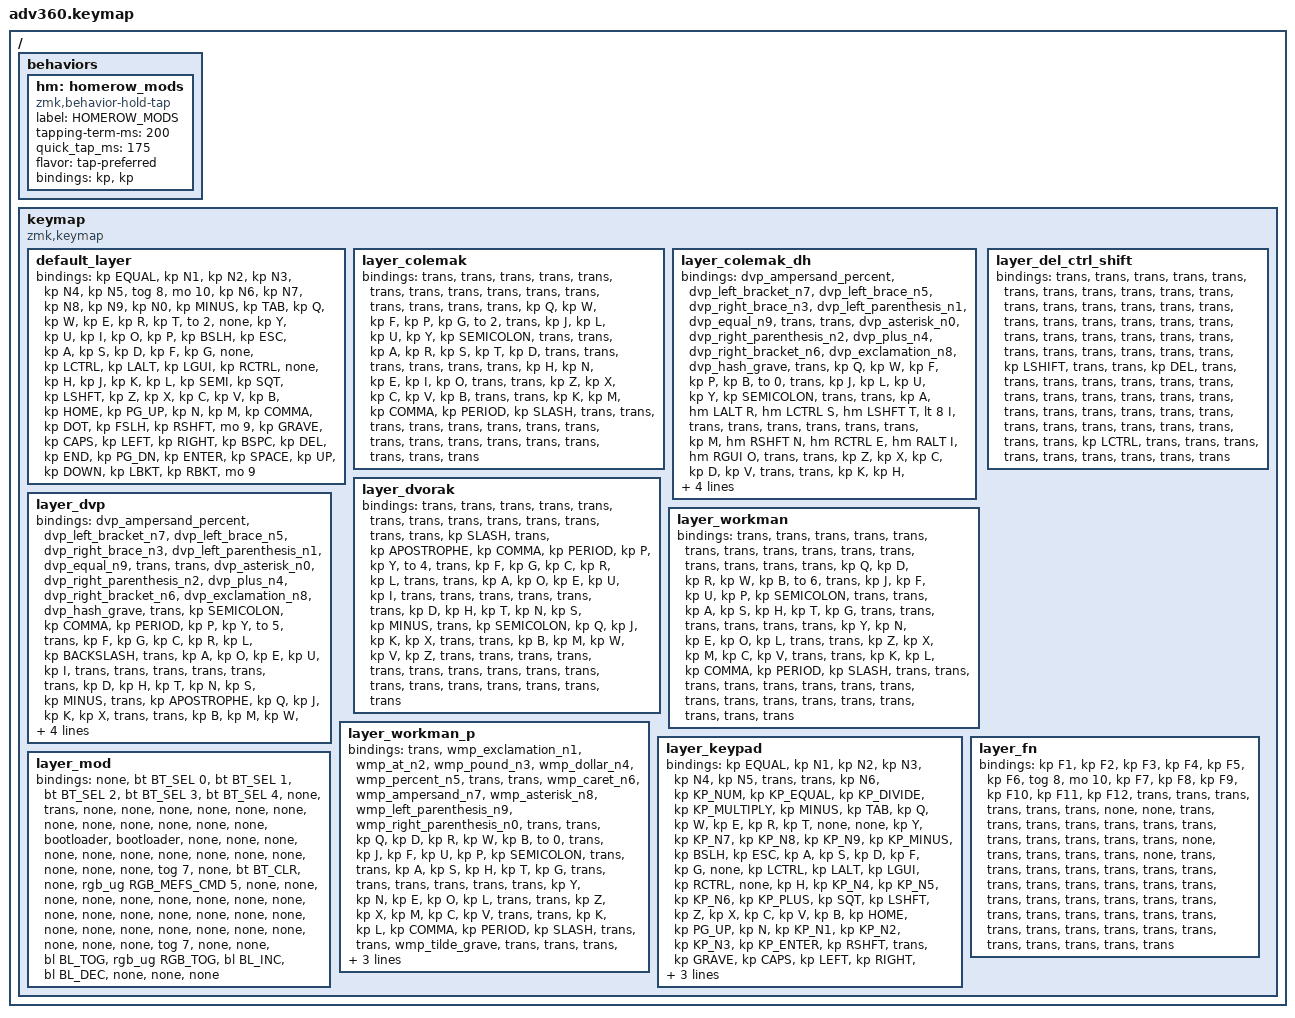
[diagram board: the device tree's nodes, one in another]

/*
 * Copyright (c) 2020 The ZMK Contributors
 *
 * SPDX-License-Identifier: MIT
 */


/* THIS FILE WAS GENERATED!
 *
 * This file was generated automatically. You may or may not want to
 * edit it directly.
 */

#include <behaviors.dtsi>
#include <dt-bindings/zmk/keys.h>
#include <dt-bindings/zmk/bt.h>
#include <dt-bindings/zmk/rgb.h>
#include <dt-bindings/zmk/backlight.h>

/ {
  behaviors {
    #include "macros.dtsi"
    #include "version.dtsi"

    hm: homerow_mods {
        compatible = "zmk,behavior-hold-tap";
        label = "HOMEROW_MODS";
        #binding-cells = <2>;
        tapping-term-ms = <200>;
        quick_tap_ms = <175>;
        flavor = "tap-preferred";
        bindings = <&kp>, <&kp>;
    };
  };

    keymap {
        compatible = "zmk,keymap";


        default_layer {
            bindings = <
 &kp EQUAL     &kp N1    &kp N2    &kp N3     &kp N4  &kp N5              &tog 8                                                                &mo 10  &kp N6  &kp N7     &kp N8    &kp N9    &kp N0  &kp MINUS
   &kp TAB      &kp Q     &kp W     &kp E      &kp R   &kp T               &to 2                                                                 &none   &kp Y   &kp U      &kp I     &kp O     &kp P   &kp BSLH
   &kp ESC      &kp A     &kp S     &kp D      &kp F   &kp G               &none  &kp LCTRL  &kp LALT                   &kp LGUI  &kp RCTRL      &none   &kp H   &kp J      &kp K     &kp L  &kp SEMI    &kp SQT
 &kp LSHFT      &kp Z     &kp X     &kp C      &kp V   &kp B                                 &kp HOME                  &kp PG_UP                         &kp N   &kp M  &kp COMMA   &kp DOT  &kp FSLH  &kp RSHFT
     &mo 9  &kp GRAVE  &kp CAPS  &kp LEFT  &kp RIGHT                    &kp BSPC    &kp DEL   &kp END                  &kp PG_DN  &kp ENTER  &kp SPACE          &kp UP   &kp DOWN  &kp LBKT  &kp RBKT      &mo 9
            >;
        };

        layer_colemak {
            bindings = <
 &trans  &trans  &trans  &trans  &trans  &trans            &trans                                                  &trans  &trans  &trans     &trans      &trans         &trans  &trans
 &trans   &kp Q   &kp W   &kp F   &kp P   &kp G             &to 2                                                  &trans   &kp J   &kp L      &kp U       &kp Y  &kp SEMICOLON  &trans
 &trans   &kp A   &kp R   &kp S   &kp T   &kp D            &trans  &trans  &trans                  &trans  &trans  &trans   &kp H   &kp N      &kp E       &kp I          &kp O  &trans
 &trans   &kp Z   &kp X   &kp C   &kp V   &kp B                            &trans                  &trans                   &kp K   &kp M  &kp COMMA  &kp PERIOD      &kp SLASH  &trans
 &trans  &trans  &trans  &trans  &trans                    &trans  &trans  &trans                  &trans  &trans  &trans          &trans     &trans      &trans         &trans  &trans
            >;
        };

        layer_colemak_dh {
            bindings = <
 &dvp_ampersand_percent  &dvp_left_bracket_n7  &dvp_left_brace_n5  &dvp_right_brace_n3  &dvp_left_parenthesis_n1  &dvp_equal_n9            &trans                                                  &trans  &dvp_asterisk_n0  &dvp_right_parenthesis_n2         &dvp_plus_n4  &dvp_right_bracket_n6  &dvp_exclamation_n8  &dvp_hash_grave
                 &trans                 &kp Q               &kp W                &kp F                     &kp P          &kp B             &to 0                                                  &trans             &kp J                      &kp L                &kp U                  &kp Y        &kp SEMICOLON           &trans
                 &trans                 &kp A          &hm LALT R         &hm LCTRL S                &hm LSHFT T        &lt 8 I            &trans  &trans  &trans                  &trans  &trans  &trans             &kp M                &hm RSHFT N          &hm RCTRL E             &hm RALT I           &hm RGUI O           &trans
                 &trans                 &kp Z               &kp X                &kp C                     &kp D          &kp V                            &trans                  &trans                             &kp K                      &kp H            &kp COMMA             &kp PERIOD            &kp SLASH           &trans
                 &trans                &trans              &trans               &trans                    &trans                           &trans  &trans  &trans                  &trans  &trans  &trans                                       &trans               &trans                 &trans               &trans           &trans
            >;
        };

        layer_dvorak {
            bindings = <
 &trans          &trans     &trans      &trans  &trans  &trans            &trans                                                  &trans  &trans  &trans  &trans  &trans  &trans  &kp SLASH
 &trans  &kp APOSTROPHE  &kp COMMA  &kp PERIOD   &kp P   &kp Y             &to 4                                                  &trans   &kp F   &kp G   &kp C   &kp R   &kp L     &trans
 &trans           &kp A      &kp O       &kp E   &kp U   &kp I            &trans  &trans  &trans                  &trans  &trans  &trans   &kp D   &kp H   &kp T   &kp N   &kp S  &kp MINUS
 &trans   &kp SEMICOLON      &kp Q       &kp J   &kp K   &kp X                            &trans                  &trans                   &kp B   &kp M   &kp W   &kp V   &kp Z     &trans
 &trans          &trans     &trans      &trans  &trans                    &trans  &trans  &trans                  &trans  &trans  &trans          &trans  &trans  &trans  &trans     &trans
            >;
        };

        layer_dvp {
            bindings = <
 &dvp_ampersand_percent  &dvp_left_bracket_n7  &dvp_left_brace_n5  &dvp_right_brace_n3  &dvp_left_parenthesis_n1  &dvp_equal_n9            &trans                                                  &trans  &dvp_asterisk_n0  &dvp_right_parenthesis_n2  &dvp_plus_n4  &dvp_right_bracket_n6  &dvp_exclamation_n8  &dvp_hash_grave
                 &trans         &kp SEMICOLON           &kp COMMA           &kp PERIOD                     &kp P          &kp Y             &to 5                                                  &trans             &kp F                      &kp G         &kp C                  &kp R                &kp L    &kp BACKSLASH
                 &trans                 &kp A               &kp O                &kp E                     &kp U          &kp I            &trans  &trans  &trans                  &trans  &trans  &trans             &kp D                      &kp H         &kp T                  &kp N                &kp S        &kp MINUS
                 &trans        &kp APOSTROPHE               &kp Q                &kp J                     &kp K          &kp X                            &trans                  &trans                             &kp B                      &kp M         &kp W                  &kp V                &kp Z           &trans
                 &trans     &dvp_dollar_tilde              &trans               &trans                    &trans                           &trans  &trans  &trans                  &trans  &trans  &trans                                       &trans        &trans              &kp SLASH        &dvp_at_caret           &trans
            >;
        };

        layer_workman {
            bindings = <
 &trans  &trans  &trans  &trans  &trans  &trans            &trans                                                  &trans  &trans  &trans     &trans      &trans         &trans  &trans
 &trans   &kp Q   &kp D   &kp R   &kp W   &kp B             &to 6                                                  &trans   &kp J   &kp F      &kp U       &kp P  &kp SEMICOLON  &trans
 &trans   &kp A   &kp S   &kp H   &kp T   &kp G            &trans  &trans  &trans                  &trans  &trans  &trans   &kp Y   &kp N      &kp E       &kp O          &kp L  &trans
 &trans   &kp Z   &kp X   &kp M   &kp C   &kp V                            &trans                  &trans                   &kp K   &kp L  &kp COMMA  &kp PERIOD      &kp SLASH  &trans
 &trans  &trans  &trans  &trans  &trans                    &trans  &trans  &trans                  &trans  &trans  &trans          &trans     &trans      &trans         &trans  &trans
            >;
        };

        layer_workman_p {
            bindings = <
 &trans  &wmp_exclamation_n1  &wmp_at_n2  &wmp_pound_n3  &wmp_dollar_n4  &wmp_percent_n5            &trans                                                  &trans  &wmp_caret_n6  &wmp_ampersand_n7  &wmp_asterisk_n8      &wmp_left_parenthesis_n9       &wmp_right_parenthesis_n0  &trans
 &trans                &kp Q       &kp D          &kp R           &kp W            &kp B             &to 0                                                  &trans          &kp J              &kp F             &kp U                         &kp P                   &kp SEMICOLON  &trans
 &trans                &kp A       &kp S          &kp H           &kp T            &kp G            &trans  &trans  &trans                  &trans  &trans  &trans          &kp Y              &kp N             &kp E                         &kp O                           &kp L  &trans
 &trans                &kp Z       &kp X          &kp M           &kp C            &kp V                            &trans                  &trans                          &kp K              &kp L         &kp COMMA                    &kp PERIOD                       &kp SLASH  &trans
 &trans     &wmp_tilde_grave      &trans         &trans          &trans                             &trans  &trans  &trans                  &trans  &trans  &trans                            &trans            &trans  &wmp_left_brace_left_bracket  &wmp_right_brace_right_bracket  &trans
            >;
        };

        layer_del_ctrl_shift {
            bindings = <
 &trans  &trans  &trans  &trans  &trans  &trans            &trans                                                       &trans  &trans  &trans  &trans  &trans  &trans  &trans
 &trans  &trans  &trans  &trans  &trans  &trans            &trans                                                       &trans  &trans  &trans  &trans  &trans  &trans  &trans
 &trans  &trans  &trans  &trans  &trans  &trans            &trans  &kp LSHIFT  &trans                  &trans  &kp DEL  &trans  &trans  &trans  &trans  &trans  &trans  &trans
 &trans  &trans  &trans  &trans  &trans  &trans                                &trans                  &trans                   &trans  &trans  &trans  &trans  &trans  &trans
 &trans  &trans  &trans  &trans  &trans                    &trans   &kp LCTRL  &trans                  &trans   &trans  &trans          &trans  &trans  &trans  &trans  &trans
            >;
        };

        layer_keypad {
            bindings = <
 &kp EQUAL     &kp N1    &kp N2    &kp N3     &kp N4  &kp N5              &trans                                                                &trans  &kp N6  &kp KP_NUM  &kp KP_EQUAL  &kp KP_DIVIDE  &kp KP_MULTIPLY  &kp MINUS
   &kp TAB      &kp Q     &kp W     &kp E      &kp R   &kp T               &none                                                                 &none   &kp Y   &kp KP_N7     &kp KP_N8      &kp KP_N9     &kp KP_MINUS   &kp BSLH
   &kp ESC      &kp A     &kp S     &kp D      &kp F   &kp G               &none  &kp LCTRL  &kp LALT                   &kp LGUI  &kp RCTRL      &none   &kp H   &kp KP_N4     &kp KP_N5      &kp KP_N6      &kp KP_PLUS    &kp SQT
 &kp LSHFT      &kp Z     &kp X     &kp C      &kp V   &kp B                                 &kp HOME                  &kp PG_UP                         &kp N   &kp KP_N1     &kp KP_N2      &kp KP_N3     &kp KP_ENTER  &kp RSHFT
    &trans  &kp GRAVE  &kp CAPS  &kp LEFT  &kp RIGHT                    &kp BSPC    &kp DEL   &kp END                  &kp PG_DN  &kp ENTER  &kp KP_N0              &kp UP      &kp DOWN     &kp KP_DOT         &kp RBKT     &trans
            >;
        };

        layer_fn {
            bindings = <
 &kp F1  &kp F2  &kp F3  &kp F4  &kp F5  &kp F6            &tog 8                                                  &mo 10  &kp F7  &kp F8  &kp F9  &kp F10  &kp F11  &kp F12
 &trans  &trans  &trans  &trans  &trans  &trans             &none                                                   &none  &trans  &trans  &trans   &trans   &trans   &trans
 &trans  &trans  &trans  &trans  &trans  &trans             &none  &trans  &trans                  &trans  &trans   &none  &trans  &trans  &trans   &trans   &trans   &trans
 &trans  &trans  &trans  &trans  &trans  &trans                            &trans                  &trans                  &trans  &trans  &trans   &trans   &trans   &trans
 &trans  &trans  &trans  &trans  &trans                    &trans  &trans  &trans                  &trans  &trans  &trans          &trans  &trans   &trans   &trans   &trans
            >;
        };

        layer_mod {
            bindings = <
  &none  &bt BT_SEL 0  &bt BT_SEL 1  &bt BT_SEL 2  &bt BT_SEL 3  &bt BT_SEL 4                  &none                                                                          &trans   &none       &none       &none   &none   &none   &none
  &none         &none         &none         &none         &none         &none            &bootloader                                                                     &bootloader   &none       &none       &none   &none   &none   &none
  &none         &none         &none         &none         &none         &none                  &none  &tog 7   &none                  &bt BT_CLR       &none  &rgb_ug RGB_MEFS_CMD 5   &none       &none       &none   &none   &none   &none
  &none         &none         &none         &none         &none         &none                                  &none                       &none                                       &none       &none       &none   &none   &none   &none
  &none         &none         &none         &none         &none                                &none  &tog 7   &none                       &none  &bl BL_TOG         &rgb_ug RGB_TOG          &bl BL_INC  &bl BL_DEC   &none   &none   &none
            >;
        };

    };
};
